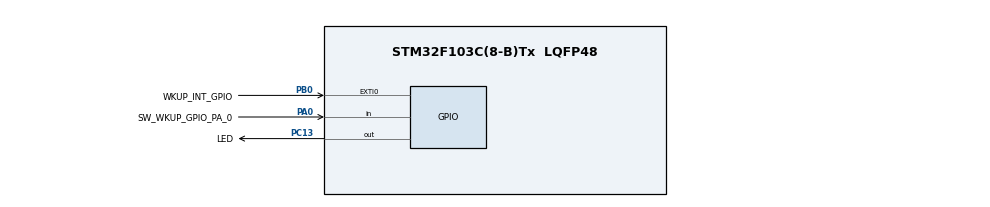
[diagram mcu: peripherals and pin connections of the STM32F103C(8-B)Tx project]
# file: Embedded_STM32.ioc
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IWDG.Reload=999
Mcu.Family=STM32F1
Mcu.Name=STM32F103C(8-B)Tx
Mcu.Package=LQFP48
NVIC.EXTI0_IRQn=true\:0\:0\:false\:false\:true\:true\:true\:true
NVIC.PriorityGroup=NVIC_PRIORITYGROUP_4
PA0-WKUP.GPIO_Label=SW_WKUP_GPIO_PA_0
PA0-WKUP.GPIO_PuPd=GPIO_PULLDOWN
PA0-WKUP.Signal=GPIO_Input
PA13.Mode=Serial_Wire
PA13.Signal=SYS_JTMS-SWDIO
PA14.Mode=Serial_Wire
PA14.Signal=SYS_JTCK-SWCLK
PB0.GPIO_Label=WKUP_INT_GPIO
PB0.GPIO_ModeDefaultEXTI=GPIO_MODE_IT_FALLING
PB0.GPIO_PuPd=GPIO_PULLUP
PB0.Signal=GPXTI0
PC13-TAMPER-RTC.GPIO_Label=LED
PC13-TAMPER-RTC.GPIO_Speed=GPIO_SPEED_FREQ_LOW
PC13-TAMPER-RTC.PinState=GPIO_PIN_SET
PC13-TAMPER-RTC.Signal=GPIO_Output
ProjectManager.HeapSize=0x200
ProjectManager.StackSize=0x400
ProjectManager.TargetToolchain=STM32CubeIDE
RCC.APB1Freq_Value=8000000
RCC.APB2Freq_Value=8000000
TIM2.Period=65535
TIM2.Prescaler=7
VP_IWDG_VS_IWDG.Mode=IWDG_Activate
VP_TIM2_VS_ClockSourceINT.Mode=Internal
board=custom

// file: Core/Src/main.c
/* USER CODE BEGIN Header */
/**
 ******************************************************************************
 * @file           : main.c
 * @brief          : Main program body
 ******************************************************************************
 * @attention
 *
 * Copyright (c) 2026 STMicroelectronics.
 * All rights reserved.
 *
 * This software is licensed under terms that can be found in the LICENSE file
 * in the root directory of this software component.
 * If no LICENSE file comes with this software, it is provided AS-IS.
 *
 ******************************************************************************
 */
/* USER CODE END Header */
#include "main.h"

/* USER CODE BEGIN Includes */
#include "ecu_state_manager.h"   /* ECU 상태 관리: 시작 절차, 잠들기 절차                */
#include "mode_manager.h"        /* 모드 관리: 슬립 조건 판단                            */
#include "indicator.h"           /* 상태 표시: 시작 LED 패턴                             */
#include "scheduler.h"           /* 10ms 주기 스케줄러 (TIM2 1µs 카운터 체크, 인터럽트 없음) */
/* USER CODE END Includes */

IWDG_HandleTypeDef hiwdg;

TIM_HandleTypeDef htim2;

void SystemClock_Config(void);
static void MX_GPIO_Init(void);
static void MX_TIM2_Init(void);
static void MX_IWDG_Init(void);

int main(void)
{

  /* MCU Configuration--------------------------------------------------------*/

  /* Reset of all peripherals, Initializes the Flash interface and the Systick. */
  HAL_Init();

  /* USER CODE BEGIN Init */
  EcuM_EarlyInit();   /* 잠들기 요청이면 IWDG 시작 전에 바로 Standby (돌아오지 않음) */

  /* USER CODE END Init */

  /* Configure the system clock */
  SystemClock_Config();

  /* Initialize all configured peripherals */
  MX_GPIO_Init();
  MX_TIM2_Init();
  MX_IWDG_Init();
  /* USER CODE BEGIN 2 */
  __HAL_DBGMCU_FREEZE_IWDG();   /* 디버거로 멈춘 동안 IWDG도 멈춤 (DBGMCU_CR.DBG_IWDG_STOP) */
  EcuM_Init();   /* 리셋 원인 판단, 웨이크 횟수 처리 */
  Indicator_ShowStartup(EcuM_GetStartupReason(), EcuM_GetWakeCount());   /* 시작 LED 패턴 */
  Sch_Init();    /* TIM2 1µs 카운터 시작 → Sch_Run()이 10ms마다 Task_10ms() 실행 */

  /* USER CODE END 2 */

  /* Infinite loop */
  /* USER CODE BEGIN WHILE */
	while (1) {
		Sch_Run();             /* 10ms마다 Task_10ms() (LED 표시, 슬립 요청) */
		BswM_MainFunction();   /* 슬립 조건 판단 → 맞으면 EcuM_GoSleep() (돌아오지 않음) → EcuM_EarlyInit()에서 Standby */

    /* USER CODE END WHILE */

	}
}

void SystemClock_Config(void)
{
  RCC_OscInitTypeDef RCC_OscInitStruct = {0};
  RCC_ClkInitTypeDef RCC_ClkInitStruct = {0};

  /** Initializes the RCC Oscillators according to the specified parameters
  * in the RCC_OscInitTypeDef structure.
  */
  RCC_OscInitStruct.OscillatorType = RCC_OSCILLATORTYPE_HSI|RCC_OSCILLATORTYPE_LSI;
  RCC_OscInitStruct.HSIState = RCC_HSI_ON;
  RCC_OscInitStruct.HSICalibrationValue = RCC_HSICALIBRATION_DEFAULT;
  RCC_OscInitStruct.LSIState = RCC_LSI_ON;
  RCC_OscInitStruct.PLL.PLLState = RCC_PLL_NONE;
  if (HAL_RCC_OscConfig(&RCC_OscInitStruct) != HAL_OK)
  {
    Error_Handler();
  }

  /** Initializes the CPU, AHB and APB buses clocks
  */
  RCC_ClkInitStruct.ClockType = RCC_CLOCKTYPE_HCLK|RCC_CLOCKTYPE_SYSCLK
                              |RCC_CLOCKTYPE_PCLK1|RCC_CLOCKTYPE_PCLK2;
  RCC_ClkInitStruct.SYSCLKSource = RCC_SYSCLKSOURCE_HSI;
  RCC_ClkInitStruct.AHBCLKDivider = RCC_SYSCLK_DIV1;
  RCC_ClkInitStruct.APB1CLKDivider = RCC_HCLK_DIV1;
  RCC_ClkInitStruct.APB2CLKDivider = RCC_HCLK_DIV1;

  if (HAL_RCC_ClockConfig(&RCC_ClkInitStruct, FLASH_LATENCY_0) != HAL_OK)
  {
    Error_Handler();
  }
}

static void MX_IWDG_Init(void)
{

  hiwdg.Instance = IWDG;
  hiwdg.Init.Prescaler = IWDG_PRESCALER_4;
  hiwdg.Init.Reload = 999;
  if (HAL_IWDG_Init(&hiwdg) != HAL_OK)
  {
    Error_Handler();
  }

}

static void MX_TIM2_Init(void)
{

  TIM_ClockConfigTypeDef sClockSourceConfig = {0};
  TIM_MasterConfigTypeDef sMasterConfig = {0};

  htim2.Instance = TIM2;
  htim2.Init.Prescaler = 7;
  htim2.Init.CounterMode = TIM_COUNTERMODE_UP;
  htim2.Init.Period = 65535;
  htim2.Init.ClockDivision = TIM_CLOCKDIVISION_DIV1;
  htim2.Init.AutoReloadPreload = TIM_AUTORELOAD_PRELOAD_DISABLE;
  if (HAL_TIM_Base_Init(&htim2) != HAL_OK)
  {
    Error_Handler();
  }
  sClockSourceConfig.ClockSource = TIM_CLOCKSOURCE_INTERNAL;
  if (HAL_TIM_ConfigClockSource(&htim2, &sClockSourceConfig) != HAL_OK)
  {
    Error_Handler();
  }
  sMasterConfig.MasterOutputTrigger = TIM_TRGO_RESET;
  sMasterConfig.MasterSlaveMode = TIM_MASTERSLAVEMODE_DISABLE;
  if (HAL_TIMEx_MasterConfigSynchronization(&htim2, &sMasterConfig) != HAL_OK)
  {
    Error_Handler();
  }

}

static void MX_GPIO_Init(void)
{
  GPIO_InitTypeDef GPIO_InitStruct = {0};

  /* GPIO Ports Clock Enable */
  __HAL_RCC_GPIOC_CLK_ENABLE();
  __HAL_RCC_GPIOA_CLK_ENABLE();
  __HAL_RCC_GPIOB_CLK_ENABLE();

  /*Configure GPIO pin Output Level */
  HAL_GPIO_WritePin(LED_GPIO_Port, LED_Pin, GPIO_PIN_SET);

  /*Configure GPIO pin : LED_Pin */
  GPIO_InitStruct.Pin = LED_Pin;
  GPIO_InitStruct.Mode = GPIO_MODE_OUTPUT_PP;
  GPIO_InitStruct.Pull = GPIO_NOPULL;
  GPIO_InitStruct.Speed = GPIO_SPEED_FREQ_LOW;
  HAL_GPIO_Init(LED_GPIO_Port, &GPIO_InitStruct);

  /*Configure GPIO pin : SW_WKUP_GPIO_PA_0_Pin */
  GPIO_InitStruct.Pin = SW_WKUP_GPIO_PA_0_Pin;
  GPIO_InitStruct.Mode = GPIO_MODE_INPUT;
  GPIO_InitStruct.Pull = GPIO_PULLDOWN;
  HAL_GPIO_Init(SW_WKUP_GPIO_PA_0_GPIO_Port, &GPIO_InitStruct);

  /*Configure GPIO pin : WKUP_INT_GPIO_Pin */
  GPIO_InitStruct.Pin = WKUP_INT_GPIO_Pin;
  GPIO_InitStruct.Mode = GPIO_MODE_IT_FALLING;
  GPIO_InitStruct.Pull = GPIO_PULLUP;
  HAL_GPIO_Init(WKUP_INT_GPIO_GPIO_Port, &GPIO_InitStruct);

  /* EXTI interrupt init*/
  HAL_NVIC_SetPriority(EXTI0_IRQn, 0, 0);
  HAL_NVIC_EnableIRQ(EXTI0_IRQn);

}

void Error_Handler(void)
{
	__disable_irq();
	while (1) {
	}
}
